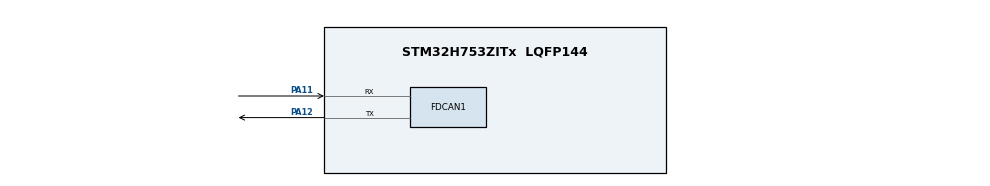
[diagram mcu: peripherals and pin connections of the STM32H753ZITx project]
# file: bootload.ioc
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CORTEX_M7.CPU_DCache=Disabled
CORTEX_M7.CPU_ICache=Disabled
CORTEX_M7.MPU_Control=MPU_PRIVILEGED_DEFAULT
CORTEX_M7.default_mode_Activation=1
FDCAN1.CalculateBaudRateNominal=500000
FDCAN1.CalculateTimeBitNominal=2000
FDCAN1.CalculateTimeQuantumNominal=200.0
FDCAN1.NominalPrescaler=15
FDCAN1.NominalTimeSeg1=7
FDCAN1.NominalTimeSeg2=2
FDCAN1.RxBuffersNbr=1
FDCAN1.RxFifo0ElmtsNbr=8
FDCAN1.StdFiltersNbr=1
FDCAN1.TxBuffersNbr=1
FDCAN1.TxEventsNbr=1
FDCAN1.TxFifoQueueElmtsNbr=8
Mcu.Family=STM32H7
Mcu.Name=STM32H753ZITx
Mcu.Package=LQFP144
NUCLEO-H753ZI.BUTTON=1
NUCLEO-H753ZI.Bsp_Common_DEMO=true
NUCLEO-H753ZI.LD1=true
NUCLEO-H753ZI.LD2=true
NUCLEO-H753ZI.LD3=true
NUCLEO-H753ZI.VCP=true
NVIC.EXTI15_10_IRQn=true\:0\:0\:false\:false\:true\:false\:true\:true
NVIC.FDCAN1_IT0_IRQn=true\:0\:0\:false\:false\:true\:true\:true\:true
NVIC.PriorityGroup=NVIC_PRIORITYGROUP_4
PA11.Mode=FDCAN_Activate
PA11.Signal=FDCAN1_RX
PA12.Mode=FDCAN_Activate
PA12.Signal=FDCAN1_TX
PC14-OSC32_IN\ (OSC32_IN).Signal=RCC_OSC32_IN
PC15-OSC32_OUT\ (OSC32_OUT).Signal=RCC_OSC32_OUT
PD8.Signal=USART3_TX
PD9.Signal=USART3_RX
PH0-OSC_IN\ (PH0).Signal=RCC_OSC_IN
PH1-OSC_OUT\ (PH1).Signal=RCC_OSC_OUT
ProjectManager.HeapSize=0x200
ProjectManager.StackSize=0x400
ProjectManager.TargetToolchain=Makefile
RCC.ADCFreq_Value=129000000
RCC.APB1Freq_Value=64000000
RCC.APB2Freq_Value=64000000
RCC.APB3Freq_Value=64000000
RCC.APB4Freq_Value=64000000
RCC.CortexFreq_Value=64000000
RCC.DIVM1=4
RCC.DIVN1=9
RCC.HCLKFreq_Value=64000000
RCC.HSE_VALUE=8000000
RCC.PLLFRACN=3072
RCC.PWR_Regulator_Voltage_Scale=PWR_REGULATOR_VOLTAGE_SCALE2
RCC.SYSCLKFreq_VALUE=64000000
RCC.USBFreq_Value=75000000
VP_MEMORYMAP_VS_MEMORYMAP.Mode=CurAppReg
VP_NUCLEO-H753ZI_VS_BSP_COMMON.Mode=COMMON
board=NUCLEO-H753ZI

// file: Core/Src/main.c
/* USER CODE BEGIN Header */
/**
  ******************************************************************************
  * @file           : main.c
  * @brief          : Main program body
  ******************************************************************************
  * @attention
  *
  * Copyright (c) 2026 STMicroelectronics.
  * All rights reserved.
  *
  * This software is licensed under terms that can be found in the LICENSE file
  * in the root directory of this software component.
  * If no LICENSE file comes with this software, it is provided AS-IS.
  *
  ******************************************************************************
  */
/* USER CODE END Header */
#include "main.h"
#include "stm32h7xx_hal_fdcan.h"

/* USER CODE BEGIN Includes */

#include "interrupts.h"

/* USER CODE END Includes */

COM_InitTypeDef BspCOMInit;
__IO uint32_t BspButtonState = BUTTON_RELEASED;

FDCAN_HandleTypeDef hfdcan1;

void SystemClock_Config(void);
static void MPU_Config(void);
static void MX_GPIO_Init(void);
static void MX_FDCAN1_Init(void);

/* USER CODE BEGIN 0 */

int err(int num)
{
	for(int i = 0; i < 2*num; ++i)
	{
		BSP_LED_Toggle(LED_RED);
		HAL_Delay(100);
	}
	HAL_Delay(500);
	return 0;
}

int noerr(int num)
{
	for(int i = 0; i < 2*num; ++i)
	{
		BSP_LED_Toggle(LED_GREEN);
		HAL_Delay(100);
	}
	HAL_Delay(500);
	return 0;
}

int parserr(HAL_StatusTypeDef stat)
{
	int i = 0;
	if(stat != HAL_OK)
	{
		switch(stat)
		{
			case HAL_ERROR: /* HAL operation completed with error   */
				++i;
			case HAL_BUSY: /* HAL concurrent process ongoing       */
				++i;
//			case HAL_INVALID_PARAM: /* HAL invalid parameter                */ // doesn't exist in HAL1
//				++i;
			case HAL_TIMEOUT: /* HAL operation exceeds user timeout   */
				++i;
			default:
				err(i);
		}
	}
	return 0;
}

// apparently this is set up automatically
void HAL_FDCAN_RxFifo0Callback(FDCAN_HandleTypeDef* hfdcan, uint32_t RxFifo0ITs)
{
	push_interrupt(1, FI_CAN_RECVD, hfdcan);
}

void HAL_FDCAN_TxEventFifoCallback(FDCAN_HandleTypeDef* hfdcan, uint32_t BufferIndexes) // [sic]
{
	push_interrupt(1, FI_CAN_SENT, hfdcan);
}

// can functions
int can_senddata(uint8_t* data, uint8_t size, uint16_t id)
{
	FDCAN_TxHeaderTypeDef head =
	{
		.Identifier = id,
		.IdType = FDCAN_STANDARD_ID,
		.TxFrameType = FDCAN_DATA_FRAME,
		.DataLength = size,
		.ErrorStateIndicator = FDCAN_ESI_ACTIVE, // or PASSIVE, what does this even mean?
		.BitRateSwitch = FDCAN_BRS_OFF,
		.FDFormat = FDCAN_CLASSIC_CAN,
		.TxEventFifoControl = FDCAN_NO_TX_EVENTS,
		.MessageMarker = 0,
	};
	HAL_FDCAN_AddMessageToTxFifoQ(&hfdcan1, &head, data);
	return 0;
}
int can_getdata(uint8_t* place, uint8_t* size, uint16_t* id)
{
	FDCAN_RxHeaderTypeDef head;
	HAL_FDCAN_GetRxMessage(&hfdcan1, 0, &head, place);
	*id = head.Identifier;
	*size = head.DataLength;
	return 0;
}

/* USER CODE END 0 */

int main(void)
{

  /* MPU Configuration--------------------------------------------------------*/
  MPU_Config();

  /* MCU Configuration--------------------------------------------------------*/

  /* Reset of all peripherals, Initializes the Flash interface and the Systick. */
  HAL_Init();

  /* Configure the system clock */
  SystemClock_Config();

  /* Initialize all configured peripherals */
  MX_GPIO_Init();
  MX_FDCAN1_Init();

  /* Initialize leds */
  BSP_LED_Init(LED_GREEN);
  BSP_LED_Init(LED_YELLOW);
  BSP_LED_Init(LED_RED);

  /* Initialize USER push-button, will be used to trigger an interrupt each time it's pressed.*/
  BSP_PB_Init(BUTTON_USER, BUTTON_MODE_EXTI);

  /* Initialize COM1 port (115200, 8 bits (7-bit data + 1 stop bit), no parity */
  BspCOMInit.BaudRate   = 115200;
  BspCOMInit.WordLength = COM_WORDLENGTH_8B;
  BspCOMInit.StopBits   = COM_STOPBITS_1;
  BspCOMInit.Parity     = COM_PARITY_NONE;
  BspCOMInit.HwFlowCtl  = COM_HWCONTROL_NONE;
  if (BSP_COM_Init(COM1, &BspCOMInit) != BSP_ERROR_NONE)
  {
    Error_Handler();
  }

  /* USER CODE BEGIN BSP */

  /* -- Sample board code to send message over COM1 port ---- */
  printf("Welcome to STM32 world !\n\r");

  /* -- Sample board code to switch on leds ---- */
//  BSP_LED_On(LED_GREEN);
//  BSP_LED_On(LED_YELLOW);
//  BSP_LED_On(LED_RED);
  noerr(2);

  interrupt_loop();

  /* USER CODE END BSP */

  /* Infinite loop */
  /* USER CODE BEGIN WHILE */
  while (1)
  {

    /* -- Sample board code for User push-button in interrupt mode ---- */
    if (BspButtonState == BUTTON_PRESSED)
    {
      /* Update button state */
      BspButtonState = BUTTON_RELEASED;
      /* -- Sample board code to toggle leds ---- */
      BSP_LED_Toggle(LED_GREEN);
      BSP_LED_Toggle(LED_YELLOW);
      BSP_LED_Toggle(LED_RED);

      /* ..... Perform your action ..... */
    }
    /* USER CODE END WHILE */

  }
}

void SystemClock_Config(void)
{
  RCC_OscInitTypeDef RCC_OscInitStruct = {0};
  RCC_ClkInitTypeDef RCC_ClkInitStruct = {0};

  /** Supply configuration update enable
  */
  HAL_PWREx_ConfigSupply(PWR_LDO_SUPPLY);

  /** Configure the main internal regulator output voltage
  */
  __HAL_PWR_VOLTAGESCALING_CONFIG(PWR_REGULATOR_VOLTAGE_SCALE2);

  while(!__HAL_PWR_GET_FLAG(PWR_FLAG_VOSRDY)) {}

  /** Initializes the RCC Oscillators according to the specified parameters
  * in the RCC_OscInitTypeDef structure.
  */
  RCC_OscInitStruct.OscillatorType = RCC_OSCILLATORTYPE_HSI;
  RCC_OscInitStruct.HSIState = RCC_HSI_DIV1;
  RCC_OscInitStruct.HSICalibrationValue = RCC_HSICALIBRATION_DEFAULT;
  RCC_OscInitStruct.PLL.PLLState = RCC_PLL_ON;
  RCC_OscInitStruct.PLL.PLLSource = RCC_PLLSOURCE_HSI;
  RCC_OscInitStruct.PLL.PLLM = 4;
  RCC_OscInitStruct.PLL.PLLN = 9;
  RCC_OscInitStruct.PLL.PLLP = 2;
  RCC_OscInitStruct.PLL.PLLQ = 2;
  RCC_OscInitStruct.PLL.PLLR = 2;
  RCC_OscInitStruct.PLL.PLLRGE = RCC_PLL1VCIRANGE_3;
  RCC_OscInitStruct.PLL.PLLVCOSEL = RCC_PLL1VCOMEDIUM;
  RCC_OscInitStruct.PLL.PLLFRACN = 3072;
  if (HAL_RCC_OscConfig(&RCC_OscInitStruct) != HAL_OK)
  {
    Error_Handler();
  }

  /** Initializes the CPU, AHB and APB buses clocks
  */
  RCC_ClkInitStruct.ClockType = RCC_CLOCKTYPE_HCLK|RCC_CLOCKTYPE_SYSCLK
                              |RCC_CLOCKTYPE_PCLK1|RCC_CLOCKTYPE_PCLK2
                              |RCC_CLOCKTYPE_D3PCLK1|RCC_CLOCKTYPE_D1PCLK1;
  RCC_ClkInitStruct.SYSCLKSource = RCC_SYSCLKSOURCE_HSI;
  RCC_ClkInitStruct.SYSCLKDivider = RCC_SYSCLK_DIV1;
  RCC_ClkInitStruct.AHBCLKDivider = RCC_HCLK_DIV1;
  RCC_ClkInitStruct.APB3CLKDivider = RCC_APB3_DIV1;
  RCC_ClkInitStruct.APB1CLKDivider = RCC_APB1_DIV1;
  RCC_ClkInitStruct.APB2CLKDivider = RCC_APB2_DIV1;
  RCC_ClkInitStruct.APB4CLKDivider = RCC_APB4_DIV1;

  if (HAL_RCC_ClockConfig(&RCC_ClkInitStruct, FLASH_LATENCY_1) != HAL_OK)
  {
    Error_Handler();
  }
}

static void MX_FDCAN1_Init(void)
{

  hfdcan1.Instance = FDCAN1;
  hfdcan1.Init.FrameFormat = FDCAN_FRAME_CLASSIC;
  hfdcan1.Init.Mode = FDCAN_MODE_NORMAL;
  hfdcan1.Init.AutoRetransmission = DISABLE;
  hfdcan1.Init.TransmitPause = DISABLE;
  hfdcan1.Init.ProtocolException = DISABLE;
  hfdcan1.Init.NominalPrescaler = 15;
  hfdcan1.Init.NominalSyncJumpWidth = 1;
  hfdcan1.Init.NominalTimeSeg1 = 7;
  hfdcan1.Init.NominalTimeSeg2 = 2;
  hfdcan1.Init.DataPrescaler = 1;
  hfdcan1.Init.DataSyncJumpWidth = 1;
  hfdcan1.Init.DataTimeSeg1 = 1;
  hfdcan1.Init.DataTimeSeg2 = 1;
  hfdcan1.Init.MessageRAMOffset = 0;
  hfdcan1.Init.StdFiltersNbr = 1;
  hfdcan1.Init.ExtFiltersNbr = 0;
  hfdcan1.Init.RxFifo0ElmtsNbr = 8;
  hfdcan1.Init.RxFifo0ElmtSize = FDCAN_DATA_BYTES_8;
  hfdcan1.Init.RxFifo1ElmtsNbr = 0;
  hfdcan1.Init.RxFifo1ElmtSize = FDCAN_DATA_BYTES_8;
  hfdcan1.Init.RxBuffersNbr = 1;
  hfdcan1.Init.RxBufferSize = FDCAN_DATA_BYTES_8;
  hfdcan1.Init.TxEventsNbr = 1;
  hfdcan1.Init.TxBuffersNbr = 1;
  hfdcan1.Init.TxFifoQueueElmtsNbr = 8;
  hfdcan1.Init.TxFifoQueueMode = FDCAN_TX_FIFO_OPERATION;
  hfdcan1.Init.TxElmtSize = FDCAN_DATA_BYTES_8;
  if (HAL_FDCAN_Init(&hfdcan1) != HAL_OK)
  {
    Error_Handler();
  }
  /* USER CODE BEGIN FDCAN1_Init 2 */
  	FDCAN_FilterTypeDef filter =
	{
		.IdType = FDCAN_STANDARD_ID,
		.FilterIndex = 0,
		.FilterType = FDCAN_FILTER_MASK,
		.FilterConfig = FDCAN_FILTER_TO_RXFIFO0,
		.FilterID1 = 0x040,
		.FilterID2 = 0x7fc,
		.RxBufferIndex = 0,
		.IsCalibrationMsg = 0,
	};
	HAL_FDCAN_ConfigFilter(&hfdcan1, &filter);
	HAL_FDCAN_ActivateNotification(&hfdcan1, FDCAN_IT_TX_COMPLETE | FDCAN_IT_RX_FIFO0_NEW_MESSAGE, 0);
	// apparently, no callback setting is needed as HAL_FDCAN_RxFifo0Callback is weak, so overwrite it.
	HAL_FDCAN_Start(&hfdcan1);
  /* USER CODE END FDCAN1_Init 2 */

}

static void MX_GPIO_Init(void)
{

  /* GPIO Ports Clock Enable */
  __HAL_RCC_GPIOC_CLK_ENABLE();
  __HAL_RCC_GPIOH_CLK_ENABLE();
  __HAL_RCC_GPIOA_CLK_ENABLE();

}

 /* MPU Configuration */

void MPU_Config(void)
{
  MPU_Region_InitTypeDef MPU_InitStruct = {0};

  /* Disables the MPU */
  HAL_MPU_Disable();

  /** Initializes and configures the Region and the memory to be protected
  */
  MPU_InitStruct.Enable = MPU_REGION_ENABLE;
  MPU_InitStruct.Number = MPU_REGION_NUMBER0;
  MPU_InitStruct.BaseAddress = 0x0;
  MPU_InitStruct.Size = MPU_REGION_SIZE_4GB;
  MPU_InitStruct.SubRegionDisable = 0x87;
  MPU_InitStruct.TypeExtField = MPU_TEX_LEVEL0;
  MPU_InitStruct.AccessPermission = MPU_REGION_NO_ACCESS;
  MPU_InitStruct.DisableExec = MPU_INSTRUCTION_ACCESS_DISABLE;
  MPU_InitStruct.IsShareable = MPU_ACCESS_SHAREABLE;
  MPU_InitStruct.IsCacheable = MPU_ACCESS_NOT_CACHEABLE;
  MPU_InitStruct.IsBufferable = MPU_ACCESS_NOT_BUFFERABLE;

  HAL_MPU_ConfigRegion(&MPU_InitStruct);
  /* Enables the MPU */
  HAL_MPU_Enable(MPU_PRIVILEGED_DEFAULT);

}

/**
  * @brief BSP Push Button callback
  * @param Button Specifies the pressed button
  * @retval None
  */
void BSP_PB_Callback(Button_TypeDef Button)
{
  if (Button == BUTTON_USER)
  {
    BspButtonState = BUTTON_PRESSED;
  }
}

void Error_Handler(void)
{
  __disable_irq();
  while (1)
  {
  }
}
